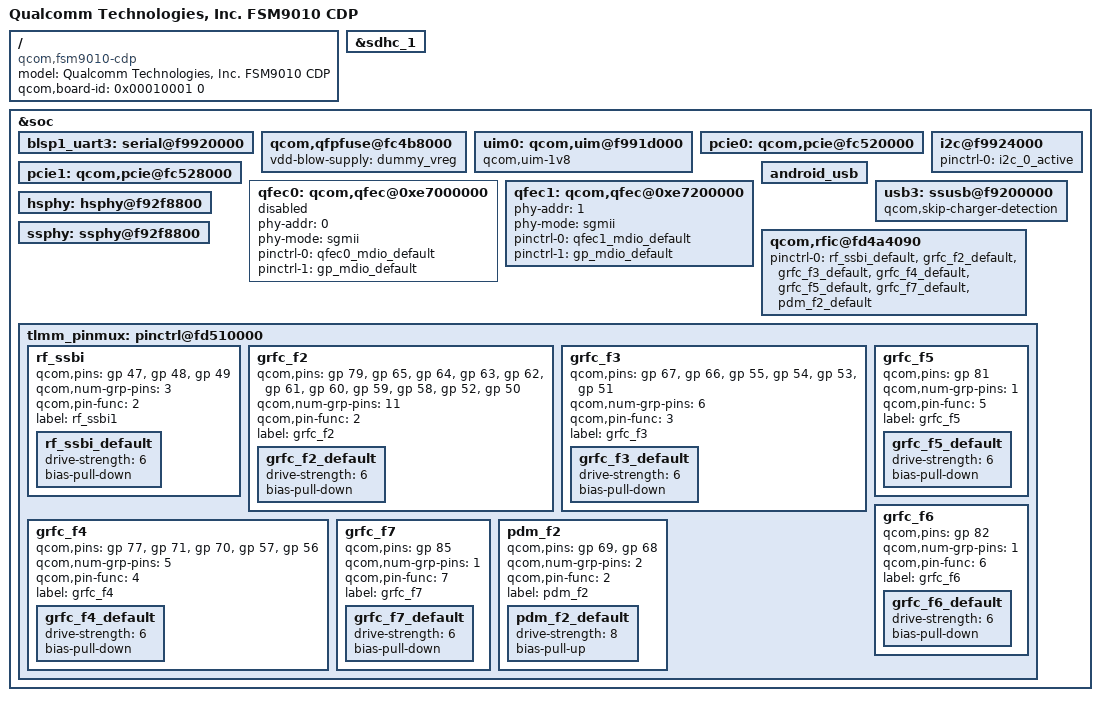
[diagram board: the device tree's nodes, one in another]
/* Copyright (c) 2014-2016, The Linux Foundation. All rights reserved.
 *
 * This program is free software; you can redistribute it and/or modify
 * it under the terms of the GNU General Public License version 2 and
 * only version 2 as published by the Free Software Foundation.
 *
 * This program is distributed in the hope that it will be useful,
 * but WITHOUT ANY WARRANTY; without even the implied warranty of
 * MERCHANTABILITY or FITNESS FOR A PARTICULAR PURPOSE.  See the
 * GNU General Public License for more details.
 */

/dts-v1/;

#include "fsm9010.dtsi"

/ {
	model = "Qualcomm Technologies, Inc. FSM9010 CDP";
	compatible = "qcom,fsm9010-cdp", "qcom,fsm9010", "qcom,cdp";
	qcom,board-id = <0x00010001 0>;
};

&sdhc_1 {
	status = "ok";
};

&soc {
	blsp1_uart3: serial@f9920000 {
		status = "ok";
	};

	qcom,qfpfuse@fc4b8000 {
		status = "ok";
		vdd-blow-supply = <&dummy_vreg>;
	};

	uim0: qcom,uim@f991d000 {
		status = "ok";
		qcom,uim-1v8;
	};

	pcie0: qcom,pcie@fc520000 {
		status = "ok";
	};

	pcie1: qcom,pcie@fc528000 {
		status = "ok";
	};

	i2c@f9924000 {
		pinctrl-names = "default";
		pinctrl-0 = <&i2c_0_active>;
		status = "ok";
	};

	qfec0: qcom,qfec@0xe7000000 {
		phy-addr = <0>;
		phy-mode = "sgmii";
		pinctrl-names = "active", "deactive";
		pinctrl-0 = <&qfec0_mdio_default>;
		pinctrl-1 = <&gp_mdio_default>;
		status = "disabled";
	};


	qfec1: qcom,qfec@0xe7200000 {
		phy-addr = <1>;
		phy-mode = "sgmii";
		pinctrl-names = "active", "deactive";
		pinctrl-0 = <&qfec1_mdio_default>;
		pinctrl-1 = <&gp_mdio_default>;
		status = "ok";
	};

	android_usb {
		status= "ok";
	};

	usb3: ssusb@f9200000 {
		qcom,skip-charger-detection;
		status = "ok";
	};

	hsphy:  hsphy@f92f8800 {
		status = "ok";
	};

	ssphy: ssphy@f92f8800 {
		status = "ok";
	};

	qcom,rfic@fd4a4090 {
		pinctrl-names = "default";
		pinctrl-0 = <&rf_ssbi_default &grfc_f2_default &grfc_f3_default
			&grfc_f4_default &grfc_f5_default
			&grfc_f7_default &pdm_f2_default>;
	};

	tlmm_pinmux: pinctrl@fd510000 {
		rf_ssbi {
			qcom,pins = <&gp 47>, <&gp 48>, <&gp 49>;
			qcom,num-grp-pins = <3>;
			qcom,pin-func = <2>;
			label = "rf_ssbi1";
			/* default state */
			rf_ssbi_default: rf_ssbi_default {
				drive-strength = <6>;
				bias-pull-down;
			};
		};

		grfc_f2 {
			qcom,pins = <&gp 79>, <&gp 65>, <&gp 64>, <&gp 63>,
			<&gp 62>, <&gp 61>, <&gp 60>, <&gp 59>, <&gp 58>,
			<&gp 52>, <&gp 50>;
			qcom,num-grp-pins = <11>;
			qcom,pin-func = <2>;
			label = "grfc_f2";
			/* default state */
			grfc_f2_default: grfc_f2_default {
				drive-strength = <6>;
				bias-pull-down;
			};
		};

		grfc_f3 {
			qcom,pins = <&gp 67>, <&gp 66>, <&gp 55>, <&gp 54>,
				<&gp 53>, <&gp 51>;
			qcom,num-grp-pins = <6>;
			qcom,pin-func = <3>;
			label = "grfc_f3";
			/* default state */
			grfc_f3_default: grfc_f3_default {
				drive-strength = <6>;
				bias-pull-down;
			};
		};

		grfc_f4 {
			qcom,pins = <&gp 77>, <&gp 71>, <&gp 70>, <&gp 57>,
			<&gp 56>;
			qcom,num-grp-pins = <5>;
			qcom,pin-func = <4>;
			label = "grfc_f4";
			/* default state */
			grfc_f4_default: grfc_f4_default {
				drive-strength = <6>;
				bias-pull-down;
			};
		};

		grfc_f5 {
			qcom,pins = <&gp 81>;
			qcom,num-grp-pins = <1>;
			qcom,pin-func = <5>;
			label = "grfc_f5";
			/* default state */
			grfc_f5_default: grfc_f5_default {
				drive-strength = <6>;
				bias-pull-down;
			};
		};

		grfc_f6 {
			qcom,pins = <&gp 82>;
			qcom,num-grp-pins = <1>;
			qcom,pin-func = <6>;
			label = "grfc_f6";
			/* default state */
			grfc_f6_default: grfc_f6_default {
				drive-strength = <6>;
				bias-pull-down;
			};
		};

		grfc_f7 {
			qcom,pins = <&gp 85>;
			qcom,num-grp-pins = <1>;
			qcom,pin-func = <7>;
			label = "grfc_f7";
			/* default state */
			grfc_f7_default: grfc_f7_default {
				drive-strength = <6>;
				bias-pull-down;
			};
		};

		pdm_f2 {
			qcom,pins = <&gp 69>, <&gp 68>;
			qcom,num-grp-pins = <2>;
			qcom,pin-func = <2>;
			label = "pdm_f2";
			/* default state */
			pdm_f2_default: pdm_f2_default {
				drive-strength = <8>;
				bias-pull-up;
			};
		};
	};
};
